AUTOSAR XML (schema 00046)
package /SWCs/SWCs_EABS
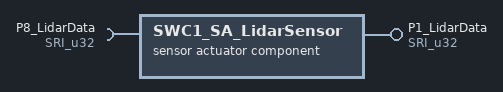
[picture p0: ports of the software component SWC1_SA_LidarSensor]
  sensor actuator sw component type SWC1_SA_LidarSensor
    provide port P1_LidarData: provided-interface=SRI_u32
    require port P8_LidarData: required-interface=SRI_u32
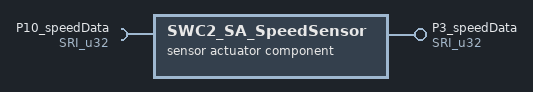
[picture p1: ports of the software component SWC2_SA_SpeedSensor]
  sensor actuator sw component type SWC2_SA_SpeedSensor
    provide port P3_speedData: provided-interface=SRI_u32
    require port P10_speedData: required-interface=SRI_u32
  sensor actuator sw component type SWC6_SA_WarningLED
    require port P6_warningLedIndicator: required-interface=SRI_bool
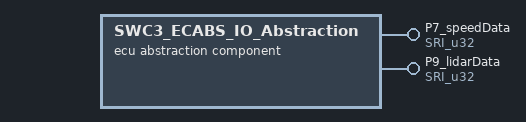
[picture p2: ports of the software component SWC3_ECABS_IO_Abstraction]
  ecu abstraction sw component type SWC3_ECABS_IO_Abstraction
    provide port P7_speedData: provided-interface=SRI_u32
    provide port P9_lidarData: provided-interface=SRI_u32
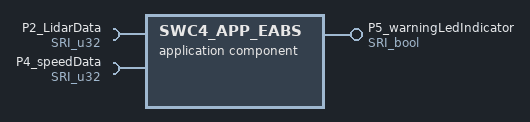
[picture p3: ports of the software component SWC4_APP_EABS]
  application sw component type SWC4_APP_EABS
    require port P2_LidarData: required-interface=SRI_u32
    require port P4_speedData: required-interface=SRI_u32
    provide port P5_warningLedIndicator: provided-interface=SRI_bool
  parameter sw component type SWC5_PARM_DistanceParameters
  complex device driver sw component type SWC7_CDD_Braking
  service sw component type SWC8_SRVS_DigM
  nv block sw component type SWC9_NV_Flash
